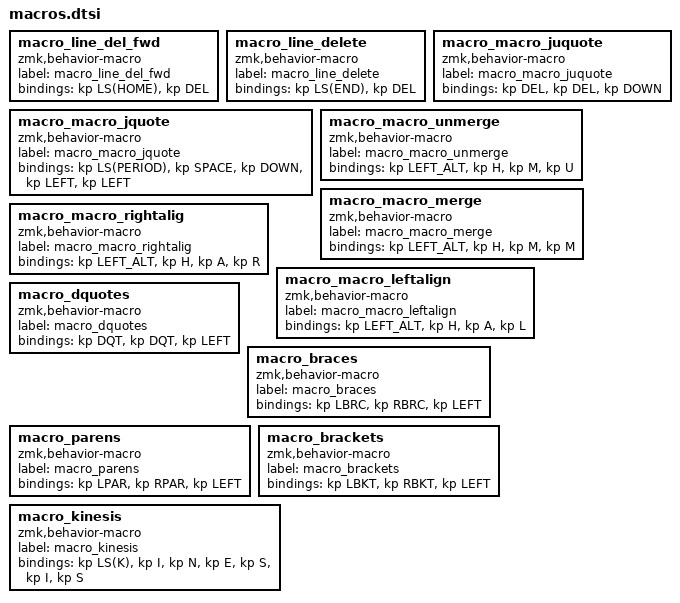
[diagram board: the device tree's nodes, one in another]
macro_line_del_fwd: macro_line_del_fwd{
compatible = "zmk,behavior-macro";
label = "macro_line_del_fwd";
#binding-cells = <0>;
bindings = <&kp LS(HOME)>, <&kp DEL>;
};
macro_line_delete: macro_line_delete{
compatible = "zmk,behavior-macro";
label = "macro_line_delete";
#binding-cells = <0>;
bindings = <&kp LS(END)>, <&kp DEL>;
};
macro_macro_juquote: macro_macro_juquote{
compatible = "zmk,behavior-macro";
label = "macro_macro_juquote";
#binding-cells = <0>;
bindings = <&kp DEL>, <&kp DEL>, <&kp DOWN>;
};
macro_macro_jquote: macro_macro_jquote{
compatible = "zmk,behavior-macro";
label = "macro_macro_jquote";
#binding-cells = <0>;
bindings = <&kp LS(PERIOD)>, <&kp SPACE>, <&kp DOWN>, <&kp LEFT>, <&kp LEFT>;
};
macro_macro_unmerge: macro_macro_unmerge{
compatible = "zmk,behavior-macro";
label = "macro_macro_unmerge";
#binding-cells = <0>;
bindings = <&kp LEFT_ALT>, <&kp H>, <&kp M>, <&kp U>;
};
macro_macro_merge: macro_macro_merge{
compatible = "zmk,behavior-macro";
label = "macro_macro_merge";
#binding-cells = <0>;
bindings = <&kp LEFT_ALT>, <&kp H>, <&kp M>, <&kp M>;
};
macro_macro_rightalig: macro_macro_rightalig{
compatible = "zmk,behavior-macro";
label = "macro_macro_rightalig";
#binding-cells = <0>;
bindings = <&kp LEFT_ALT>, <&kp H>, <&kp A>, <&kp R>;
};
macro_macro_leftalign: macro_macro_leftalign{
compatible = "zmk,behavior-macro";
label = "macro_macro_leftalign";
#binding-cells = <0>;
bindings = <&kp LEFT_ALT>, <&kp H>, <&kp A>, <&kp L>;
};
macro_dquotes: macro_dquotes{
compatible = "zmk,behavior-macro";
label = "macro_dquotes";
#binding-cells = <0>;
bindings = <&kp DQT>, <&kp DQT>, <&kp LEFT>;
};
macro_braces: macro_braces{
compatible = "zmk,behavior-macro";
label = "macro_braces";
#binding-cells = <0>;
bindings = <&kp LBRC>, <&kp RBRC>, <&kp LEFT>;
};
macro_parens: macro_parens{
compatible = "zmk,behavior-macro";
label = "macro_parens";
#binding-cells = <0>;
bindings = <&kp LPAR>, <&kp RPAR>, <&kp LEFT>;
};
macro_brackets: macro_brackets{
compatible = "zmk,behavior-macro";
label = "macro_brackets";
#binding-cells = <0>;
bindings = <&kp LBKT>, <&kp RBKT>, <&kp LEFT>;
};
macro_kinesis: macro_kinesis{
compatible = "zmk,behavior-macro";
label = "macro_kinesis";
#binding-cells = <0>;
bindings = <&kp LS(K)>, <&kp I>, <&kp N>, <&kp E>, <&kp S>, <&kp I>, <&kp S>;
};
